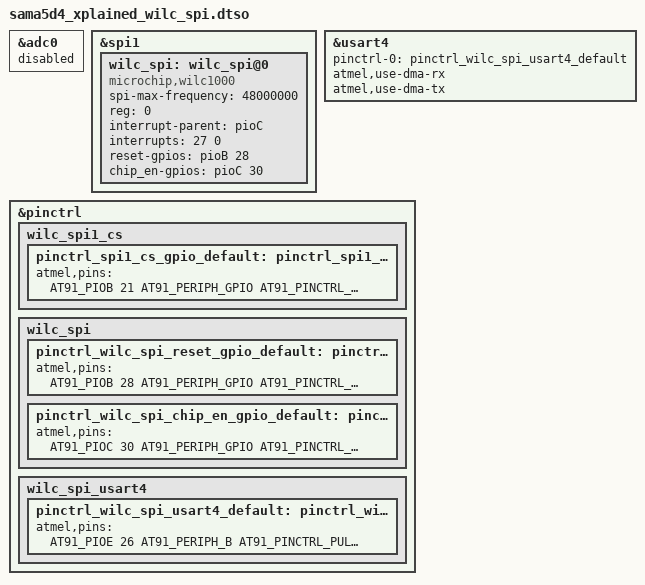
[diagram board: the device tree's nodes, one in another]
// SPDX-License-Identifier: (GPL-2.0+ OR MIT)
/*
 * Device Tree file for SAMA5D4 Xplained
 * board overlay blob for WILC SPI devices.
 *
 * Copyright (C) 2019 Microchip Technology, Inc.
 * Author: Claudiu Beznea <claudiu.beznea@microchip.com>
 *
 */
/dts-v1/;
/plugin/;

#include "dt-bindings/pinctrl/at91.h"

&adc0 {
	status = "disabled"; /* conflict on PC30. */
};

&spi1 {
	#address-cells = <1>;
	#size-cells = <0>;
	status = "okay";

	wilc_spi: wilc_spi@0 {
		compatible = "microchip,wilc1000", "microchip,wilc3000";
		spi-max-frequency = <48000000>;
		reg = <0>;
		interrupt-parent = <&pioC>;
		interrupts = <27 0>;
		reset-gpios = <&pioB 28 0>;
		chip_en-gpios = <&pioC 30 0>;
		status = "okay";
	};
};

&usart4 {
	pinctrl-names = "default";
	pinctrl-0 = <&pinctrl_wilc_spi_usart4_default>;
	atmel,use-dma-rx;
	atmel,use-dma-tx;
	status = "okay";
};

&pinctrl {
	wilc_spi1_cs {
		pinctrl_spi1_cs_gpio_default: pinctrl_spi1_cs_gpio {
			atmel,pins = <AT91_PIOB 21 AT91_PERIPH_GPIO AT91_PINCTRL_NONE>;
		};
	};

	wilc_spi {
		pinctrl_wilc_spi_reset_gpio_default: pinctrl_wilc_spi_reset_gpio {
			atmel,pins = <AT91_PIOB 28 AT91_PERIPH_GPIO AT91_PINCTRL_NONE>;
		};

		pinctrl_wilc_spi_chip_en_gpio_default: pinctrl_wilc_spi_chip_en_gpio {
			atmel,pins = <AT91_PIOC 30 AT91_PERIPH_GPIO AT91_PINCTRL_NONE>;
		};
	};

	wilc_spi_usart4 {
		pinctrl_wilc_spi_usart4_default: pinctrl_wilc_spi_usart4  {
			atmel,pins = <AT91_PIOE 26 AT91_PERIPH_B AT91_PINCTRL_PULL_UP	/* RXD */
				      AT91_PIOE 27 AT91_PERIPH_B AT91_PINCTRL_NONE	/* TXD */
				      AT91_PIOE 28 AT91_PERIPH_B AT91_PINCTRL_NONE	/* RTS */
				      AT91_PIOE 0 AT91_PERIPH_C AT91_PINCTRL_NONE>;	/* CTS */
		};
	};
};
